# EFR32MG24A120F1536GM48 register map
Vendor: Silicon Labs; Series: EFR32; File version: B
Registers are 32-bit, read-write, reset 0x0 unless marked. A register's access mark holds for its fields unless they carry their own. Offsets are from the block's base; [hi:lo] are bit positions; {n}, {i} and the like mark numbered series.

## DMEM_S — DMEM_S Registers
Base 0x400B4000
Same registers: DMEM_NS 0x500B4000
0x00 IPVERSION ro reset 0x2
  [1:0] IPVERSION — New BitField
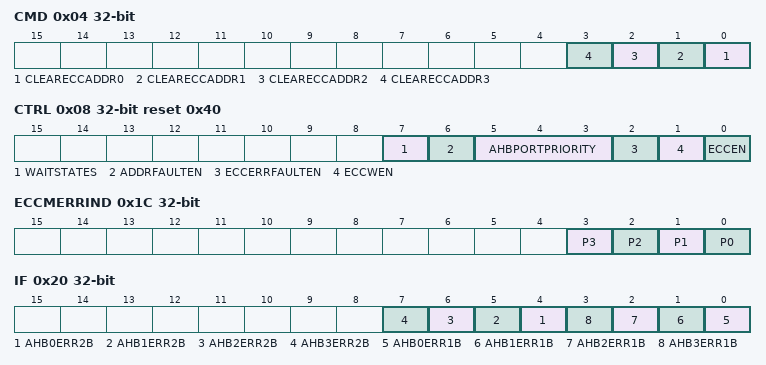
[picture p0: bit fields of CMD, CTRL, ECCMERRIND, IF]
0x04 CMD wo
  [n] CLEARECCADDR{n} (n=0..3) — Clear ECCERRADDR{n}
0x08 CTRL reset 0x40
  [7] WAITSTATES — RAM read wait states
  [6] ADDRFAULTEN — Address fault bus fault enable
  [5:3] AHBPORTPRIORITY — AHB port arbitration priority
    0=NONE (No AHB port have raised priority.); {v}=PORT{v-1} (AHB port {v-1} has raised priority.) (v=1..4)
  [2] ECCERRFAULTEN — ECC Error bus fault enable
  [1] ECCWEN — Enable ECC syndrome writes
  [0] ECCEN — Enable ECC functionality
{0xC+4i} ECCERRADDR{i} ro (i=0..3)
  [31:0] ADDR — ECC Error Address
0x1C ECCMERRIND ro
  [3] P3 — Multiple ECC errors on AHB port 2
  [2] P2 — Multiple ECC errors on AHB port 2
  [1] P1 — Multiple ECC errors on AHB port 1
  [0] P0 — Multiple ECC errors on AHB port 0
0x20 IF
  [n+4] AHB{n}ERR2B (n=0..3) — AHB{n} 2-bit ECC Error Interrupt Flag
  [n] AHB{n}ERR1B (n=0..3) — AHB{n} 1-bit ECC Error Interrupt Flag
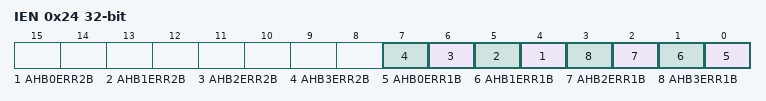
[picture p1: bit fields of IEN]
0x24 IEN
  [n+4] AHB{n}ERR2B (n=0..3) — AHB{n} 2-bit ECC Error Interrupt Enable
  [n] AHB{n}ERR1B (n=0..3) — AHB{n} 1-bit ECC Error Interrupt Enable
0x28 RAMBANKSVALID reset 0xFFFFFFFF
  [15:0] RAMBANKSVALID — Enable bits for RAM banks 0-31
    1=BLK0 (Enable RAM block0); 3=BLK0TO1 (Enable RAM block0 to block1); 7=BLK0TO2 (Enable RAM block0 to block2); 15=BLK0TO3 (Enable RAM block0 to block3); 31=BLK0TO4 (Enable RAM block0 to block4); 63=BLK0TO5 (Enable RAM block0 to block5); 127=BLK0TO6 (Enable RAM block0 to block6); 255=BLK0TO7 (Enable RAM block0 to block7); 0x1FF=BLK0TO8 (Enable RAM block0 to block8); 0x3FF=BLK0TO9 (Enable RAM block0 to block9); 0x7FF=BLK0TO10 (Enable RAM block0 to block10); 0xFFF=BLK0TO11 (Enable RAM block0 to block11); 0x1FFF=BLK0TO12 (Enable RAM block0 to block12); 0x3FFF=BLK0TO13 (Enable RAM block0 to block13); 0x7FFF=BLK0TO14 (Enable RAM block0 to block14); 0xFFFF=BLK0TO15 (Enable RAM block0 to block15)
0x2C CFGSRTOP
  [0] SRTOP — Sequential region on top
0x30 CFGSRMAP reset 0xFFFFFFFF
  [15:0] MAP
{0x34+4i} CFGIU{i}MAP (i=0..3)
  [15:0] MAP

## SMU_S_CFGNS — SMU_S_CFGNS Registers
Base 0x4400C000
Same registers: SMU_NS_CFGNS 0x5400C000
0x04 NSSTATUS ro
  [0] SMUNSLOCK
    0=UNLOCKED; 1=LOCKED
0x08 NSLOCK wo
  [23:0] SMUNSLOCKKEY
    0xACCE55=UNLOCK (Unlocks Registers)
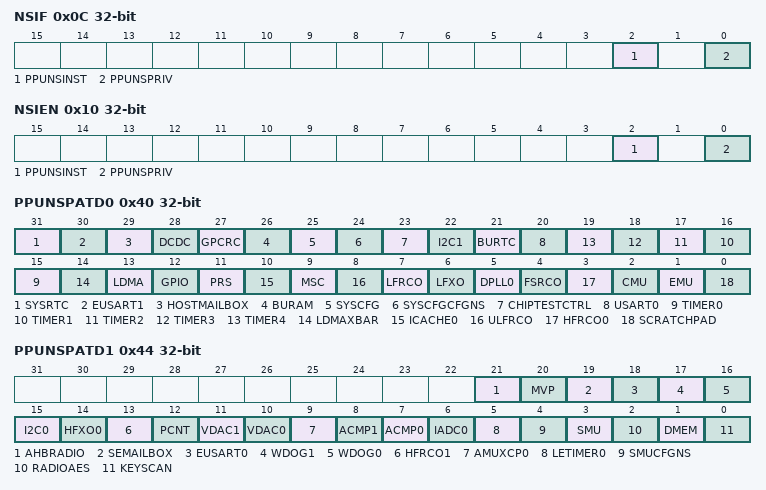
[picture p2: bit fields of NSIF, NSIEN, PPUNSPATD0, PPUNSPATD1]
0x0C NSIF
  [2] PPUNSINST — PPUNS Instruction Interrupt Flag
  [0] PPUNSPRIV — PPUNS Privilege Interrupt Flag
0x10 NSIEN
  [2] PPUNSINST — PPUNS Instruction Interrupt Enable
  [0] PPUNSPRIV — PPUNS Privilege Interrupt Enable
0x40 PPUNSPATD0 — Set peripheral bits to 1 to mark as privileged access only
  [31] SYSRTC — SYSRTC Privileged Access
  [30] EUSART1 — EUSART1 Privileged Access
  [29] HOSTMAILBOX — HOSTMAILBOX Privileged Access
  [28] DCDC — DCDC Privileged Access
  [27] GPCRC — GPCRC Privileged Access
  [26] BURAM — BURAM Privileged Access
  [25] SYSCFG — SYSCFG Privileged Access
  [24] SYSCFGCFGNS — SYSCFGCFGNS Privileged Access
  [23] CHIPTESTCTRL — CHIPTESTCTRL Privileged Access
  [22] I2C1 — I2C1 Privileged Access
  [21] BURTC — BURTC Privileged Access
  [20] USART0 — USART0 Privileged Access
  [n+15] TIMER{n} (n=0..4) — TIMER{n} Privileged Access
  [14] LDMAXBAR — LDMAXBAR Privileged Access
  [13] LDMA — LDMA Privileged Access
  [12] GPIO — GPIO Privileged Access
  [11] PRS — PRS Privileged Access
  [10] ICACHE0 — ICACHE0 Privileged Access
  [9] MSC — MSC Privileged Access
  [8] ULFRCO — ULFRCO Privileged Access
  [7] LFRCO — LFRCO Privileged Access
  [6] LFXO — LFXO Privileged Access
  [5] DPLL0 — DPLL0 Privileged Access
  [4] FSRCO — FSRCO Privileged Access
  [3] HFRCO0 — HFRCO0 Privileged Access
  [2] CMU — CMU Privileged Access
  [1] EMU — EMU Privileged Access
  [0] SCRATCHPAD — SCRATCHPAD Privileged Access
0x44 PPUNSPATD1 — Set peripheral bits to 1 to mark as privileged access only
  [21] AHBRADIO — AHBRADIO Privileged Access
  [20] MVP — MVP Privileged Access
  [19] SEMAILBOX — SEMAILBOX Privileged Access
  [18] EUSART0 — EUSART0 Privileged Access
  [17] WDOG1 — WDOG1 Privileged Access
  [16] WDOG0 — WDOG0 Privileged Access
  [15] I2C0 — I2C0 Privileged Access
  [14] HFXO0 — HFXO0 Privileged Access
  [13] HFRCO1 — HFRCO1 Privileged Access
  [12] PCNT — PCNT Privileged Access
  [11] VDAC1 — VDAC1 Privileged Access
  [10] VDAC0 — VDAC0 Privileged Access
  [9] AMUXCP0 — AMUXCP0 Privileged Access
  [8] ACMP1 — ACMP1 Privileged Access
  [7] ACMP0 — ACMP0 Privileged Access
  [6] IADC0 — IADC0 Privileged Access
  [5] LETIMER0 — LETIMER0 Privileged Access
  [4] SMUCFGNS — SMUCFGNS Privileged Access
  [3] SMU — SMU Privileged Access
  [2] RADIOAES — RADIOAES Privileged Access
  [1] DMEM — DMEM Privileged Access
  [0] KEYSCAN — KEYSCAN Privileged Access
0x140 PPUNSFS ro
  [7:0] PPUFSPERIPHID — Peripheral I
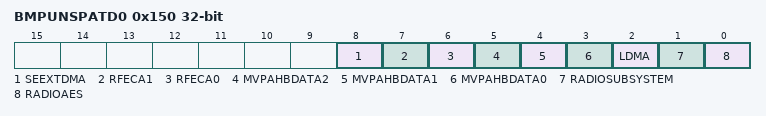
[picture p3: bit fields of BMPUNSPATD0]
0x150 BMPUNSPATD0
  [8] SEEXTDMA — SEEXTDMA privileged mode
  [7] RFECA1 — RFECA1 privileged mode
  [6] RFECA0 — RFECA0 privileged mode
  [5] MVPAHBDATA2 — MVPAHBDATA2 privileged mode
  [4] MVPAHBDATA1 — MVPAHBDATA1 privileged mode
  [3] MVPAHBDATA0 — MVPAHBDATA0 privileged mode
  [2] LDMA — MCU LDMA privileged mode
  [1] RADIOSUBSYSTEM — RADIO subsystem manager privileged mode
  [0] RADIOAES — RADIO AES DMA privileged mode
